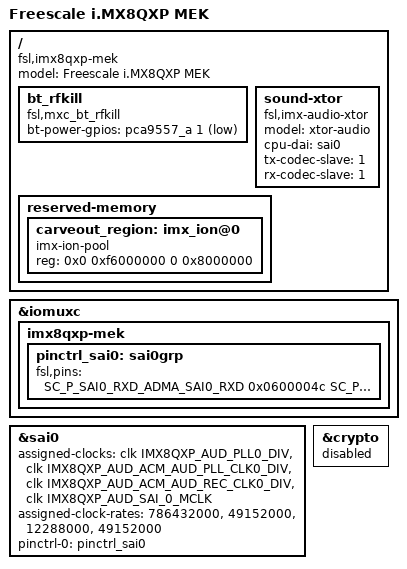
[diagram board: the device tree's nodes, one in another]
/*
 * Copyright 2017-2020 NXP
 *
 * This program is free software; you can redistribute it and/or
 * modify it under the terms of the GNU General Public License
 * as published by the Free Software Foundation; either version 2
 * of the License, or (at your option) any later version.
 *
 * This program is distributed in the hope that it will be useful,
 * but WITHOUT ANY WARRANTY; without even the implied warranty of
 * MERCHANTABILITY or FITNESS FOR A PARTICULAR PURPOSE.  See the
 * GNU General Public License for more details.
 */

#include "fsl-imx8qxp.dtsi"
#include "fsl-imx8x-mek.dtsi"

/ {
	model = "Freescale i.MX8QXP MEK";
	compatible = "fsl,imx8qxp-mek", "fsl,imx8qxp";

	bt_rfkill {
		compatible = "fsl,mxc_bt_rfkill";
		bt-power-gpios = <&pca9557_a 1 GPIO_ACTIVE_LOW>;
		status ="okay";
	};

	sound-xtor {
		compatible = "fsl,imx-audio-xtor";
		model = "xtor-audio";
		cpu-dai = <&sai0>;
		tx-codec-slave = <1>;
		rx-codec-slave = <1>;
		status = "okay";
	};
};

&iomuxc {
	imx8qxp-mek {
		pinctrl_sai0: sai0grp {
			fsl,pins = <
				SC_P_SAI0_RXD_ADMA_SAI0_RXD 0x0600004c
				SC_P_SAI0_TXC_ADMA_SAI0_TXC 0x0600004c
				SC_P_SAI0_TXFS_ADMA_SAI0_TXFS 0x0600004c
				SC_P_SAI0_TXD_ADMA_SAI0_TXD 0x0600006c
			>;
		};
	};
};

&sai0 {
	assigned-clocks = <&clk IMX8QXP_AUD_PLL0_DIV>,
			<&clk IMX8QXP_AUD_ACM_AUD_PLL_CLK0_DIV>,
			<&clk IMX8QXP_AUD_ACM_AUD_REC_CLK0_DIV>,
			<&clk IMX8QXP_AUD_SAI_0_MCLK>;
	assigned-clock-rates = <786432000>, <49152000>, <12288000>, <49152000>;
	pinctrl-names = "default";
	pinctrl-0 = <&pinctrl_sai0>;
	status = "okay";
};


&crypto {
	status = "disabled";
};

/ {
	reserved-memory {
		#address-cells = <2>;
		#size-cells = <2>;
		ranges;

		carveout_region: imx_ion@0 {
			compatible = "imx-ion-pool";
			reg = <0x0 0xf6000000 0 0x8000000>;
		};
	};
};
